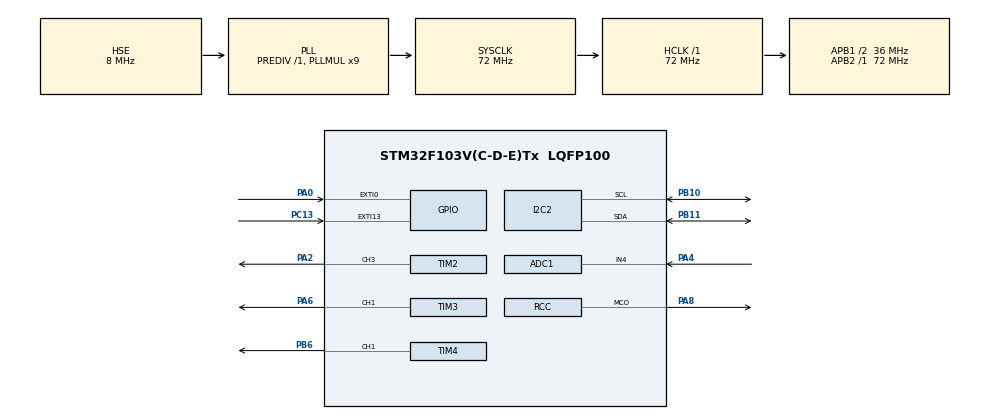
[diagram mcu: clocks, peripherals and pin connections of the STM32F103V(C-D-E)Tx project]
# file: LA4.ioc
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ADC1.Channel-0\#ChannelRegularConversion=ADC_CHANNEL_4
ADC1.NbrOfConversionFlag=1
ADC1.Rank-0\#ChannelRegularConversion=1
ADC1.SamplingTime-0\#ChannelRegularConversion=ADC_SAMPLETIME_55CYCLES_5
ADC1.master=1
Mcu.Family=STM32F1
Mcu.Name=STM32F103V(C-D-E)Tx
Mcu.Package=LQFP100
NVIC.EXTI0_IRQn=true\:0\:0\:false\:false\:true\:true\:true\:true
NVIC.EXTI15_10_IRQn=true\:0\:0\:false\:false\:true\:true\:true\:true
NVIC.PriorityGroup=NVIC_PRIORITYGROUP_4
OSC_IN.Mode=HSE-External-Oscillator
OSC_IN.Signal=RCC_OSC_IN
OSC_OUT.Mode=HSE-External-Oscillator
OSC_OUT.Signal=RCC_OSC_OUT
PA0-WKUP.Signal=GPXTI0
PA13.Mode=Serial_Wire
PA13.Signal=SYS_JTMS-SWDIO
PA14.Mode=Serial_Wire
PA14.Signal=SYS_JTCK-SWCLK
PA2.Signal=S_TIM2_CH3
PA4.Signal=ADCx_IN4
PA6.Signal=S_TIM3_CH1
PA8.GPIO_Speed=GPIO_SPEED_FREQ_HIGH
PA8.Mode=Clock-out
PA8.Signal=RCC_MCO
PB10.Mode=I2C
PB10.Signal=I2C2_SCL
PB11.Mode=I2C
PB11.Signal=I2C2_SDA
PB6.Signal=S_TIM4_CH1
PC13-TAMPER-RTC.Signal=GPXTI13
PC14-OSC32_IN.Mode=LSE-External-Oscillator
PC14-OSC32_IN.Signal=RCC_OSC32_IN
PC15-OSC32_OUT.Mode=LSE-External-Oscillator
PC15-OSC32_OUT.Signal=RCC_OSC32_OUT
ProjectManager.HeapSize=0x200
ProjectManager.StackSize=0x400
ProjectManager.TargetToolchain=STM32CubeIDE
RCC.ADCPresc=RCC_ADCPCLK2_DIV6
RCC.AHBFreq_Value=72000000
RCC.APB1CLKDivider=RCC_HCLK_DIV2
RCC.APB1Freq_Value=36000000
RCC.APB1TimFreq_Value=72000000
RCC.APB2Freq_Value=72000000
RCC.APB2TimFreq_Value=72000000
RCC.HCLKFreq_Value=72000000
RCC.PLLMUL=RCC_PLL_MUL9
RCC.PLLSourceVirtual=RCC_PLLSOURCE_HSE
RCC.SYSCLKFreq_VALUE=72000000
RCC.SYSCLKSource=RCC_SYSCLKSOURCE_PLLCLK
RCC.USBFreq_Value=72000000
SH.ADCx_IN4.0=ADC1_IN4,IN4
SH.S_TIM2_CH3.0=TIM2_CH3,PWM Generation3 CH3
SH.S_TIM3_CH1.0=TIM3_CH1,PWM Generation1 CH1
SH.S_TIM4_CH1.0=TIM4_CH1,PWM Generation1 CH1
TIM2.Channel-PWM\ Generation3\ CH3=TIM_CHANNEL_3
TIM2.Period=1999
TIM2.Prescaler=79
TIM2.Pulse-PWM\ Generation3\ CH3=50
TIM3.Channel-PWM\ Generation1\ CH1=TIM_CHANNEL_1
TIM3.Period=113
TIM3.Prescaler=0
TIM3.Pulse-PWM\ Generation1\ CH1=91
TIM3.TIM_MasterOutputTrigger=TIM_TRGO_UPDATE
TIM3.TIM_MasterSlaveMode=TIM_MASTERSLAVEMODE_ENABLE
TIM4.Channel-PWM\ Generation1\ CH1=TIM_CHANNEL_1
TIM4.Period=13332
TIM4.Pulse-PWM\ Generation1\ CH1=3999
VP_TIM2_VS_ClockSourceINT.Mode=Internal
VP_TIM4_VS_ClockSourceITR.Mode=TriggerSource_ITR2
VP_TIM4_VS_ControllerModeClock.Mode=Clock Mode
board=custom

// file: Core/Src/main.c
/* USER CODE BEGIN Header */
/**
  ******************************************************************************
  * @file           : main.c
  * @brief          : Main program body
  ******************************************************************************
  * @attention
  *
  * Copyright (c) 2024 STMicroelectronics.
  * All rights reserved.
  *
  * This software is licensed under terms that can be found in the LICENSE file
  * in the root directory of this software component.
  * If no LICENSE file comes with this software, it is provided AS-IS.
  *
  ******************************************************************************
  */
/* USER CODE END Header */
#include "main.h"
#include "adc.h"
#include "i2c.h"
#include "tim.h"
#include "gpio.h"

/* USER CODE BEGIN Includes */
#include "gpio.h"
#include "lcd.h"

/* USER CODE END Includes */

void SystemClock_Config(void);

int main(void)
{

  /* MCU Configuration--------------------------------------------------------*/

  /* Reset of all peripherals, Initializes the Flash interface and the Systick. */
  HAL_Init();

  /* Configure the system clock */
  SystemClock_Config();

  /* Initialize all configured peripherals */
  MX_GPIO_Init();
  MX_TIM2_Init();
  MX_TIM3_Init();
  MX_TIM4_Init();
  MX_I2C2_Init();
  MX_ADC1_Init();
  /* USER CODE BEGIN 2 */
  LCD_INIT();
  HAL_ADCEx_Calibration_Start(&hadc1);

  /* USER CODE END 2 */

  /* Infinite loop */
  while (1)
  {

  }
}

void SystemClock_Config(void)
{
  RCC_OscInitTypeDef RCC_OscInitStruct = {0};
  RCC_ClkInitTypeDef RCC_ClkInitStruct = {0};
  RCC_PeriphCLKInitTypeDef PeriphClkInit = {0};

  /** Initializes the RCC Oscillators according to the specified parameters
  * in the RCC_OscInitTypeDef structure.
  */
  RCC_OscInitStruct.OscillatorType = RCC_OSCILLATORTYPE_HSE;
  RCC_OscInitStruct.HSEState = RCC_HSE_ON;
  RCC_OscInitStruct.HSEPredivValue = RCC_HSE_PREDIV_DIV1;
  RCC_OscInitStruct.HSIState = RCC_HSI_ON;
  RCC_OscInitStruct.PLL.PLLState = RCC_PLL_ON;
  RCC_OscInitStruct.PLL.PLLSource = RCC_PLLSOURCE_HSE;
  RCC_OscInitStruct.PLL.PLLMUL = RCC_PLL_MUL9;
  if (HAL_RCC_OscConfig(&RCC_OscInitStruct) != HAL_OK)
  {
    Error_Handler();
  }

  /** Initializes the CPU, AHB and APB buses clocks
  */
  RCC_ClkInitStruct.ClockType = RCC_CLOCKTYPE_HCLK|RCC_CLOCKTYPE_SYSCLK
                              |RCC_CLOCKTYPE_PCLK1|RCC_CLOCKTYPE_PCLK2;
  RCC_ClkInitStruct.SYSCLKSource = RCC_SYSCLKSOURCE_PLLCLK;
  RCC_ClkInitStruct.AHBCLKDivider = RCC_SYSCLK_DIV1;
  RCC_ClkInitStruct.APB1CLKDivider = RCC_HCLK_DIV2;
  RCC_ClkInitStruct.APB2CLKDivider = RCC_HCLK_DIV1;

  if (HAL_RCC_ClockConfig(&RCC_ClkInitStruct, FLASH_LATENCY_2) != HAL_OK)
  {
    Error_Handler();
  }
  PeriphClkInit.PeriphClockSelection = RCC_PERIPHCLK_ADC;
  PeriphClkInit.AdcClockSelection = RCC_ADCPCLK2_DIV6;
  if (HAL_RCCEx_PeriphCLKConfig(&PeriphClkInit) != HAL_OK)
  {
    Error_Handler();
  }
  HAL_RCC_MCOConfig(RCC_MCO, RCC_MCO1SOURCE_SYSCLK, RCC_MCODIV_1);
}

void Error_Handler(void)
{
  __disable_irq();
  while (1)
  {
  }
}
